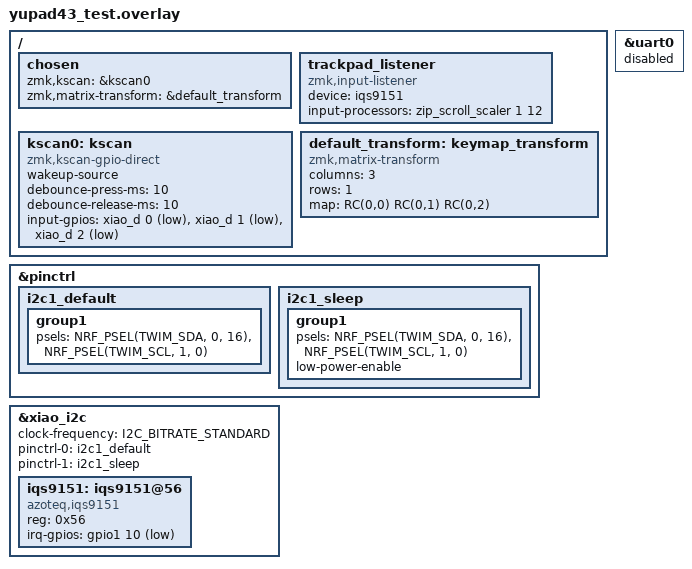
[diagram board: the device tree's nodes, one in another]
#include <input/processors.dtsi>
#include <dt-bindings/gpio/gpio.h>
#include <dt-bindings/i2c/i2c.h>
#include <dt-bindings/pinctrl/nrf-pinctrl.h>
#include <dt-bindings/zmk/matrix_transform.h>

/* yuPad43 FPC adapter: D4/D5 are not used for I2C. */
&pinctrl {
    i2c1_default: i2c1_default {
        group1 {
            psels = <NRF_PSEL(TWIM_SDA, 0, 16)>,
                    <NRF_PSEL(TWIM_SCL, 1, 0)>;
        };
    };

    i2c1_sleep: i2c1_sleep {
        group1 {
            psels = <NRF_PSEL(TWIM_SDA, 0, 16)>,
                    <NRF_PSEL(TWIM_SCL, 1, 0)>;
            low-power-enable;
        };
    };
};

/* D6/P1.11 is the yuPad43 NRST line, not a UART TX pin. */
&uart0 {
    status = "disabled";
};

&xiao_i2c {
    status = "okay";
    clock-frequency = <I2C_BITRATE_STANDARD>;
    pinctrl-0 = <&i2c1_default>;
    pinctrl-1 = <&i2c1_sleep>;
    pinctrl-names = "default", "sleep";

    iqs9151: iqs9151@56 {
        compatible = "azoteq,iqs9151";
        reg = <0x56>;
        status = "okay";
        irq-gpios = <&gpio1 10 (GPIO_ACTIVE_LOW | GPIO_PULL_UP)>;
    };
};

/ {
    chosen {
        zmk,kscan = &kscan0;
        zmk,matrix-transform = &default_transform;
    };

    trackpad_listener {
        compatible = "zmk,input-listener";
        device = <&iqs9151>;
        input-processors = <&zip_scroll_scaler 1 12>;
        status = "okay";
    };

    /* Optional key inputs; unassigned in the example keymap. */
    kscan0: kscan {
        compatible = "zmk,kscan-gpio-direct";
        wakeup-source;
        debounce-press-ms = <10>;
        debounce-release-ms = <10>;
        input-gpios = <&xiao_d 0 (GPIO_ACTIVE_LOW | GPIO_PULL_UP)>,
                      <&xiao_d 1 (GPIO_ACTIVE_LOW | GPIO_PULL_UP)>,
                      <&xiao_d 2 (GPIO_ACTIVE_LOW | GPIO_PULL_UP)>;
    };

    default_transform: keymap_transform {
        compatible = "zmk,matrix-transform";
        columns = <3>;
        rows = <1>;
        map = <RC(0,0) RC(0,1) RC(0,2)>;
    };
};
